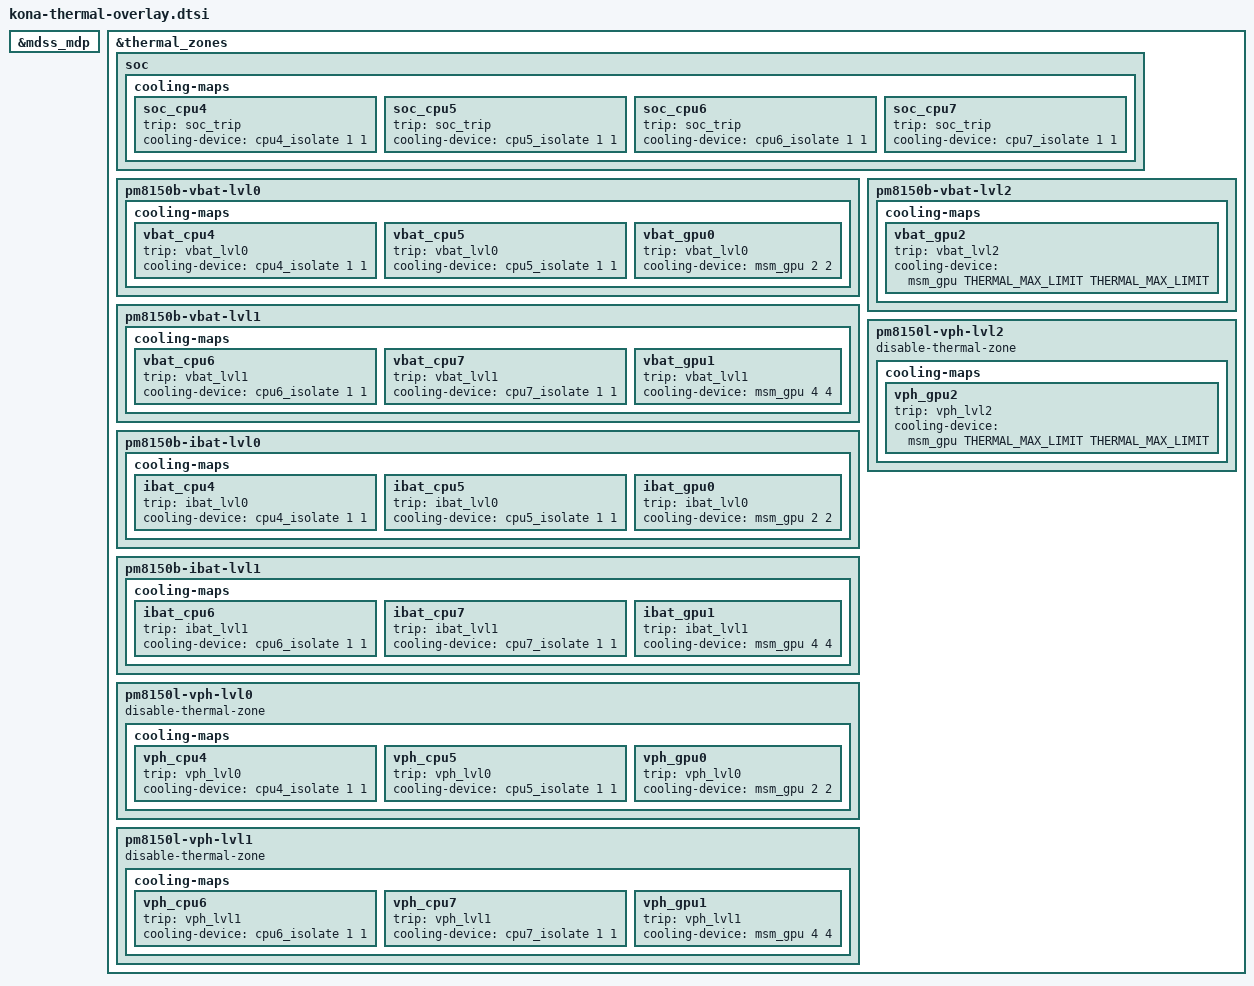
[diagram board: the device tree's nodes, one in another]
// SPDX-License-Identifier: GPL-2.0-only
/*
 * Copyright (c) 2019, The Linux Foundation. All rights reserved.
 */

#include <dt-bindings/thermal/thermal.h>

&mdss_mdp {
	#cooling-cells = <2>;
};

&thermal_zones {
	soc {
		cooling-maps {
			soc_cpu4 {
				trip = <&soc_trip>;
				cooling-device = <&cpu4_isolate 1 1>;
			};

			soc_cpu5 {
				trip = <&soc_trip>;
				cooling-device = <&cpu5_isolate 1 1>;
			};

			soc_cpu6 {
				trip = <&soc_trip>;
				cooling-device = <&cpu6_isolate 1 1>;
			};

			soc_cpu7 {
				trip = <&soc_trip>;
				cooling-device = <&cpu7_isolate 1 1>;
			};
		};
	};

	pm8150b-vbat-lvl0 {
		cooling-maps {
			vbat_cpu4 {
				trip = <&vbat_lvl0>;
				cooling-device = <&cpu4_isolate 1 1>;
			};

			vbat_cpu5 {
				trip = <&vbat_lvl0>;
				cooling-device = <&cpu5_isolate 1 1>;
			};

			vbat_gpu0 {
				trip = <&vbat_lvl0>;
				cooling-device = <&msm_gpu 2 2>;
			};
		};
	};

	pm8150b-vbat-lvl1 {
		cooling-maps {
			vbat_cpu6 {
				trip = <&vbat_lvl1>;
				cooling-device = <&cpu6_isolate 1 1>;
			};

			vbat_cpu7 {
				trip = <&vbat_lvl1>;
				cooling-device = <&cpu7_isolate 1 1>;
			};

			vbat_gpu1 {
				trip = <&vbat_lvl1>;
				cooling-device = <&msm_gpu 4 4>;
			};
		};
	};

	pm8150b-vbat-lvl2 {
		cooling-maps {
			vbat_gpu2 {
				trip = <&vbat_lvl2>;
				cooling-device = <&msm_gpu THERMAL_MAX_LIMIT
							THERMAL_MAX_LIMIT>;
			};
		};
	};

	pm8150b-ibat-lvl0 {
		cooling-maps {
			ibat_cpu4 {
				trip = <&ibat_lvl0>;
				cooling-device = <&cpu4_isolate 1 1>;
			};

			ibat_cpu5 {
				trip = <&ibat_lvl0>;
				cooling-device = <&cpu5_isolate 1 1>;
			};

			ibat_gpu0 {
				trip = <&ibat_lvl0>;
				cooling-device = <&msm_gpu 2 2>;
			};
		};
	};

	pm8150b-ibat-lvl1 {
		cooling-maps {
			ibat_cpu6 {
				trip = <&ibat_lvl1>;
				cooling-device = <&cpu6_isolate 1 1>;
			};

			ibat_cpu7 {
				trip = <&ibat_lvl1>;
				cooling-device = <&cpu7_isolate 1 1>;
			};

			ibat_gpu1 {
				trip = <&ibat_lvl1>;
				cooling-device = <&msm_gpu 4 4>;
			};
		};
	};

	pm8150l-vph-lvl0 {
		disable-thermal-zone;
		cooling-maps {
			vph_cpu4 {
				trip = <&vph_lvl0>;
				cooling-device = <&cpu4_isolate 1 1>;
			};

			vph_cpu5 {
				trip = <&vph_lvl0>;
				cooling-device = <&cpu5_isolate 1 1>;
			};

			vph_gpu0 {
				trip = <&vph_lvl0>;
				cooling-device = <&msm_gpu 2 2>;
			};
		};
	};

	pm8150l-vph-lvl1 {
		disable-thermal-zone;
		cooling-maps {
			vph_cpu6 {
				trip = <&vph_lvl1>;
				cooling-device = <&cpu6_isolate 1 1>;
			};

			vph_cpu7 {
				trip = <&vph_lvl1>;
				cooling-device = <&cpu7_isolate 1 1>;
			};

			vph_gpu1 {
				trip = <&vph_lvl1>;
				cooling-device = <&msm_gpu 4 4>;
			};
		};
	};

	pm8150l-vph-lvl2 {
		disable-thermal-zone;
		cooling-maps {
			vph_gpu2 {
				trip = <&vph_lvl2>;
				cooling-device = <&msm_gpu THERMAL_MAX_LIMIT
							THERMAL_MAX_LIMIT>;
			};
		};
	};
};
